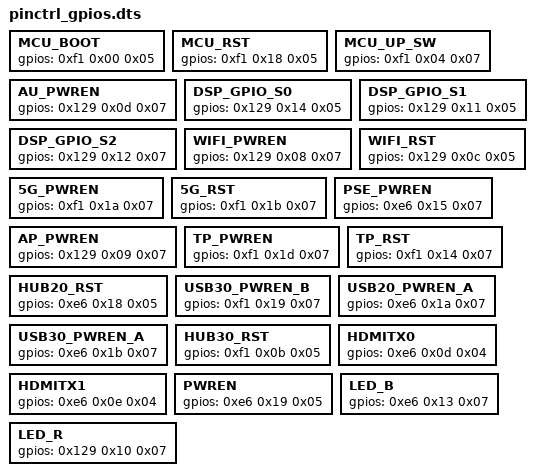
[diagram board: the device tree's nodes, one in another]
MCU_BOOT {
	gpios = <0xf1 0x00 0x05>;
};

MCU_RST {
	gpios = <0xf1 0x18 0x05>;
};

MCU_UP_SW {
	gpios = <0xf1 0x04 0x07>;
};

AU_PWREN {
	gpios = <0x129 0x0d 0x07>;
};

DSP_GPIO_S0 {
	gpios = <0x129 0x14 0x05>;
};

DSP_GPIO_S1 {
	gpios = <0x129 0x11 0x05>;
};

DSP_GPIO_S2 {
	gpios = <0x129 0x12 0x07>;
};

WIFI_PWREN {
	gpios = <0x129 0x08 0x07>;
};

WIFI_RST {
	gpios = <0x129 0x0c 0x05>;
};

5G_PWREN {
	gpios = <0xf1 0x1a 0x07>;
};

5G_RST {
	gpios = <0xf1 0x1b 0x07>;
};

PSE_PWREN {
	gpios = <0xe6 0x15 0x07>;
};

AP_PWREN {
	gpios = <0x129 0x09 0x07>;
};

TP_PWREN {
	gpios = <0xf1 0x1d 0x07>;
};

TP_RST {
	gpios = <0xf1 0x14 0x07>;
};

HUB20_RST {
	gpios = <0xe6 0x18 0x05>;
};

USB30_PWREN_B {
	gpios = <0xf1 0x19 0x07>;
};

USB20_PWREN_A {
	gpios = <0xe6 0x1a 0x07>;
};

USB30_PWREN_A {
	gpios = <0xe6 0x1b 0x07>;
};

HUB30_RST {
	gpios = <0xf1 0x0b 0x05>;
};

HDMITX0 {
	gpios = <0xe6 0x0d 0x04>;
};

HDMITX1 {
	gpios = <0xe6 0x0e 0x04>;
};

PWREN {
	gpios = <0xe6 0x19 0x05>;
};

LED_B {
	gpios = <0xe6 0x13 0x07>;
};

LED_R {
	gpios = <0x129 0x10 0x07>;
};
